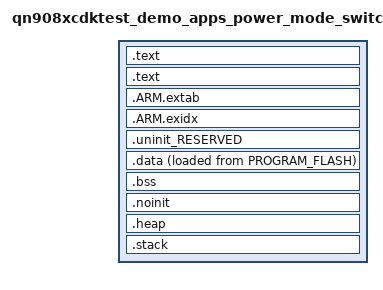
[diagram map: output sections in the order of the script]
/*
 * GENERATED FILE - DO NOT EDIT
 * Copyright (c) 2008 - 2013 Code Red Technologies Ltd, 
 * Copyright 2015, 2018 NXP
 * (c) NXP Semiconductors 2013-2019
 * Generated linker script file for QN908XC
 * Created from linkscript.ldt by FMCreateLinkLibraries
 * Using Freemarker v2.3.23
 * MCUXpresso IDE v10.3.1 [Build 2233] [2019-02-20] on 23/10/2019 3:54:11 AM
 */

INCLUDE "qn908xcdktest_demo_apps_power_mode_switch_Debug_library.ld"
INCLUDE "qn908xcdktest_demo_apps_power_mode_switch_Debug_memory.ld"

ENTRY(ResetISR)

SECTIONS
{
    /* MAIN TEXT SECTION */
    .text : ALIGN(4)
    {
        FILL(0xff)
        __vectors_start__ = ABSOLUTE(.) ;
        KEEP(*(.isr_vector))
        /* Global Section Table */
        . = ALIGN(4) ;
        __section_table_start = .;
        __data_section_table = .;
        LONG(LOADADDR(.data));
        LONG(    ADDR(.data));
        LONG(  SIZEOF(.data));
        __data_section_table_end = .;
        __bss_section_table = .;
        LONG(    ADDR(.bss));
        LONG(  SIZEOF(.bss));
        __bss_section_table_end = .;
        __section_table_end = . ;
        /* End of Global Section Table */

        *(.after_vectors*)

    } > PROGRAM_FLASH

    .text : ALIGN(4)
    {
       *(.text*)
       *(.rodata .rodata.* .constdata .constdata.*)
       . = ALIGN(4);
    } > PROGRAM_FLASH
    /*
     * for exception handling/unwind - some Newlib functions (in common
     * with C++ and STDC++) use this. 
     */
    .ARM.extab : ALIGN(4) 
    {
        *(.ARM.extab* .gnu.linkonce.armextab.*)
    } > PROGRAM_FLASH

    __exidx_start = .;

    .ARM.exidx : ALIGN(4)
    {
        *(.ARM.exidx* .gnu.linkonce.armexidx.*)
    } > PROGRAM_FLASH
    __exidx_end = .;
 
    _etext = .;
        
    /* MAIN DATA SECTION */
    .uninit_RESERVED : ALIGN(4)
    {
        KEEP(*(.bss.$RESERVED*))
        . = ALIGN(4) ;
        _end_uninit_RESERVED = .;
    } > SRAM

    /* Main DATA section (SRAM) */
    .data : ALIGN(4)
    {
       FILL(0xff)
       _data = . ;
       *(vtable)
       *(.ramfunc*)
       *(.data*)
       . = ALIGN(4) ;
       _edata = . ;
    } > SRAM AT>PROGRAM_FLASH

    /* MAIN BSS SECTION */
    .bss : ALIGN(4)
    {
        _bss = .;
        *(.bss*)
        *(COMMON)
        . = ALIGN(4) ;
        _ebss = .;
        PROVIDE(end = .);
    } > SRAM

    /* DEFAULT NOINIT SECTION */
    .noinit (NOLOAD): ALIGN(4)
    {
        _noinit = .;
        *(.noinit*) 
         . = ALIGN(4) ;
        _end_noinit = .;
    } > SRAM

    /* Reserve and place Heap within memory map */
    _HeapSize = 0x100;
    .heap :  ALIGN(4)
    {
        _pvHeapStart = .;
        . += _HeapSize;
        . = ALIGN(4);
        _pvHeapLimit = .;
    } > SRAM

    /* Reserve and place Stack within memory map */
    _StackSize = 0x800;
    .stack :  ALIGN(4)
    {
        _vStackBase = .;
        . += _StackSize;
        . = ALIGN(4);
        _vStackTop = .;
    } > SRAM

    /* Provide basic symbols giving location and size of main text
     * block, including initial values of RW data sections. Note that
     * these will need extending to give a complete picture with
     * complex images (e.g multiple Flash banks).
     */
    _image_start = LOADADDR(.text);
    _image_end = LOADADDR(.data) + SIZEOF(.data);
    _image_size = _image_end - _image_start;
}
